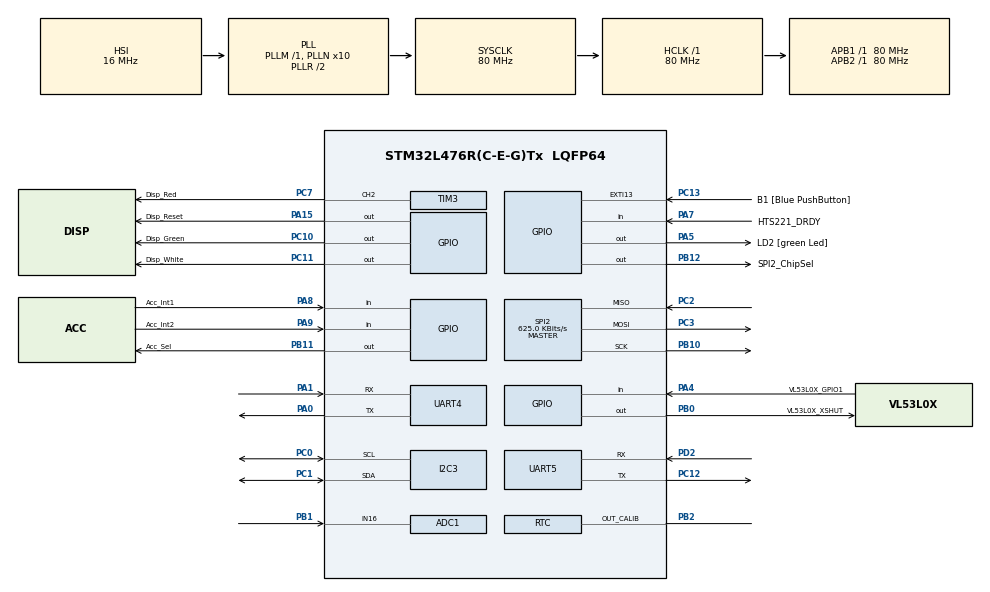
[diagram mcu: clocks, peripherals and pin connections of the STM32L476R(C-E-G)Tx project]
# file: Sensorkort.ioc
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ADC1.Channel-0\#ChannelRegularConversion=ADC_CHANNEL_16
ADC1.NbrOfConversionFlag=1
ADC1.OffsetNumber-0\#ChannelRegularConversion=ADC_OFFSET_NONE
ADC1.Rank-0\#ChannelRegularConversion=1
ADC1.SamplingTime-0\#ChannelRegularConversion=ADC_SAMPLETIME_2CYCLES_5
ADC1.master=1
Mcu.Family=STM32L4
Mcu.Name=STM32L476R(C-E-G)Tx
Mcu.Package=LQFP64
NVIC.PriorityGroup=NVIC_PRIORITYGROUP_4
PA0.Mode=Asynchronous
PA0.Signal=UART4_TX
PA1.Mode=Asynchronous
PA1.Signal=UART4_RX
PA13\ (JTMS-SWDIO).GPIO_Label=TMS
PA13\ (JTMS-SWDIO).Mode=Serial_Wire
PA13\ (JTMS-SWDIO).Signal=SYS_JTMS-SWDIO
PA14\ (JTCK-SWCLK).GPIO_Label=TCK
PA14\ (JTCK-SWCLK).Mode=Serial_Wire
PA14\ (JTCK-SWCLK).Signal=SYS_JTCK-SWCLK
PA15\ (JTDI).GPIO_Label=Disp_Reset
PA15\ (JTDI).PinState=GPIO_PIN_SET
PA15\ (JTDI).Signal=GPIO_Output
PA2.GPIO_Label=USART_TX
PA2.GPIO_Mode=GPIO_MODE_AF_PP
PA2.GPIO_PuPd=GPIO_NOPULL
PA2.GPIO_Speed=GPIO_SPEED_FREQ_VERY_HIGH
PA2.Signal=USART2_TX
PA3.GPIO_Label=USART_RX
PA3.GPIO_Mode=GPIO_MODE_AF_PP
PA3.GPIO_PuPd=GPIO_NOPULL
PA3.GPIO_Speed=GPIO_SPEED_FREQ_VERY_HIGH
PA3.Signal=USART2_RX
PA4.GPIO_Label=VL53L0X_GPIO1
PA4.Signal=GPIO_Input
PA5.GPIO_Label=LD2 [green Led]
PA5.GPIO_ModeDefaultOutputPP=GPIO_MODE_OUTPUT_PP
PA5.GPIO_PuPd=GPIO_NOPULL
PA5.GPIO_Speed=GPIO_SPEED_FREQ_LOW
PA5.Signal=GPIO_Output
PA7.GPIO_Label=HTS221_DRDY
PA7.Signal=GPIO_Input
PA8.GPIO_Label=Acc_Int1
PA8.Signal=GPIO_Input
PA9.GPIO_Label=Acc_Int2
PA9.Signal=GPIO_Input
PB0.GPIO_Label=VL53L0X_XSHUT
PB0.GPIO_ModeDefaultOutputPP=GPIO_MODE_OUTPUT_PP
PB0.PinState=GPIO_PIN_SET
PB0.Signal=GPIO_Output
PB1.Signal=ADCx_IN16
PB10.Mode=Full_Duplex_Master
PB10.Signal=SPI2_SCK
PB11.GPIO_Label=Acc_Sel
PB11.GPIO_ModeDefaultOutputPP=GPIO_MODE_OUTPUT_PP
PB11.Signal=GPIO_Output
PB12.GPIO_Label=SPI2_ChipSel
PB12.PinState=GPIO_PIN_SET
PB12.Signal=GPIO_Output
PB2.Mode=Calibration_1Hz
PB2.Signal=RTC_OUT_CALIB
PB3\ (JTDO-TRACESWO).GPIO_Label=SWO
PB3\ (JTDO-TRACESWO).Signal=SYS_JTDO-SWO
PC0.Mode=I2C
PC0.Signal=I2C3_SCL
PC1.Mode=I2C
PC1.Signal=I2C3_SDA
PC10.GPIO_Label=Disp_Green
PC10.Signal=GPIO_Output
PC11.GPIO_Label=Disp_White
PC11.Signal=GPIO_Output
PC12.Mode=Asynchronous
PC12.Signal=UART5_TX
PC13.GPIO_Label=B1 [Blue PushButton]
PC13.GPIO_ModeDefaultEXTI=GPIO_MODE_IT_FALLING
PC13.GPIO_PuPd=GPIO_NOPULL
PC13.Signal=GPXTI13
PC14-OSC32_IN\ (PC14).Mode=LSE-External-Oscillator
PC14-OSC32_IN\ (PC14).Signal=RCC_OSC32_IN
PC15-OSC32_OUT\ (PC15).Mode=LSE-External-Oscillator
PC15-OSC32_OUT\ (PC15).Signal=RCC_OSC32_OUT
PC2.Mode=Full_Duplex_Master
PC2.Signal=SPI2_MISO
PC3.Mode=Full_Duplex_Master
PC3.Signal=SPI2_MOSI
PC7.GPIO_Label=Disp_Red
PC7.Signal=S_TIM3_CH2
PD2.Mode=Asynchronous
PD2.Signal=UART5_RX
PH0-OSC_IN\ (PH0).Signal=RCC_OSC_IN
PH1-OSC_OUT\ (PH1).Signal=RCC_OSC_OUT
ProjectManager.HeapSize=0x200
ProjectManager.StackSize=0x400
ProjectManager.TargetToolchain=STM32CubeIDE
RCC.ADCFreq_Value=64000000
RCC.AHBFreq_Value=80000000
RCC.APB1Freq_Value=80000000
RCC.APB1TimFreq_Value=80000000
RCC.APB2Freq_Value=80000000
RCC.APB2TimFreq_Value=80000000
RCC.CortexFreq_Value=80000000
RCC.HCLKFreq_Value=80000000
RCC.HSE_VALUE=8000000
RCC.HSI_VALUE=16000000
RCC.MSI_VALUE=4000000
RCC.PLLN=10
RCC.PLLSourceVirtual=RCC_PLLSOURCE_HSI
RCC.PREFETCH_ENABLE=1
RCC.SYSCLKFreq_VALUE=80000000
RCC.SYSCLKSource=RCC_SYSCLKSOURCE_PLLCLK
RCC.USBFreq_Value=64000000
RCC.VCOOutputFreq_Value=160000000
RTC.Format=RTC_FORMAT_BIN
SH.ADCx_IN16.0=ADC1_IN16,IN16-Single-Ended
SH.S_TIM3_CH2.0=TIM3_CH2,PWM Generation2 CH2
SPI2.BaudRatePrescaler=SPI_BAUDRATEPRESCALER_128
SPI2.CLKPhase=SPI_PHASE_2EDGE
SPI2.CLKPolarity=SPI_POLARITY_HIGH
SPI2.CalculateBaudRate=625.0 KBits/s
SPI2.DataSize=SPI_DATASIZE_8BIT
SPI2.Direction=SPI_DIRECTION_2LINES
SPI2.FirstBit=SPI_FIRSTBIT_LSB
SPI2.Mode=SPI_MODE_MASTER
SPI2.VirtualType=VM_MASTER
TIM3.Channel-PWM\ Generation2\ CH2=TIM_CHANNEL_2
TIM3.Period=4000
VP_RTC_VS_RTC_Activate.Mode=RTC_Enabled
VP_RTC_VS_RTC_Calendar.Mode=RTC_Calendar
VP_TIM3_VS_ClockSourceINT.Mode=Internal
board=NUCLEO-L476RG

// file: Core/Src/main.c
/* USER CODE BEGIN Header */
/**
  ******************************************************************************
  * @file           : main.c
  * @brief          : Main program body
  ******************************************************************************
  * @attention
  *
  * <h2><center>&copy; Copyright (c) 2019 STMicroelectronics.
  * All rights reserved.</center></h2>
  *
  * This software component is licensed by ST under BSD 3-Clause license,
  * the "License"; You may not use this file except in compliance with the
  * License. You may obtain a copy of the License at:
  *                        opensource.org/licenses/BSD-3-Clause
  *
  ******************************************************************************
  */
/* USER CODE END Header */

#include "main.h"
#include "adc.h"
#include "i2c.h"
#include "rtc.h"
#include "spi.h"
#include "tim.h"
#include "usart.h"
#include "gpio.h"

/* USER CODE BEGIN Includes */
#include "../../Tests/Inc/display_test.h"
#include "../../Tests/Inc/rtc_test.h"
#include "../../Tests/Inc/usb_com_test.h"
#include "alt1_program.h"
/* USER CODE END Includes */

/* USER CODE BEGIN PD */
#define RUN_TEST_PROGRAM
/* USER CODE END PD */

void SystemClock_Config(void);

/* USER CODE BEGIN 0 */
#ifdef RUN_TEST_PROGRAM
extern void initialise_monitor_handles(void);
#endif
/* USER CODE END 0 */

int main(void)
{
  /* USER CODE BEGIN 1 */
#undef RUN_TEST_PROGRAM
  /* USER CODE END 1 */

  /* MCU Configuration--------------------------------------------------------*/

  /* Reset of all peripherals, Initializes the Flash interface and the Systick. */
  HAL_Init();

  /* Configure the system clock */
  SystemClock_Config();

  /* Initialize all configured peripherals */
  MX_GPIO_Init();
  MX_ADC1_Init();
  MX_I2C3_Init();
  MX_RTC_Init();
  MX_SPI2_Init();
  MX_UART4_Init();
  MX_UART5_Init();
  MX_TIM3_Init();
  /* USER CODE BEGIN 2 */
#ifdef RUN_TEST_PROGRAM
  display_test_program();
#else
  alt1_program();
#endif
  /* USER CODE END 2 */

  /* Infinite loop */
  while (1)
  {

  }
}

void SystemClock_Config(void)
{
  RCC_OscInitTypeDef RCC_OscInitStruct = {0};
  RCC_ClkInitTypeDef RCC_ClkInitStruct = {0};
  RCC_PeriphCLKInitTypeDef PeriphClkInit = {0};

  /** Initializes the CPU, AHB and APB busses clocks
  */
  RCC_OscInitStruct.OscillatorType = RCC_OSCILLATORTYPE_HSI|RCC_OSCILLATORTYPE_LSI;
  RCC_OscInitStruct.HSIState = RCC_HSI_ON;
  RCC_OscInitStruct.HSICalibrationValue = RCC_HSICALIBRATION_DEFAULT;
  RCC_OscInitStruct.LSIState = RCC_LSI_ON;
  RCC_OscInitStruct.PLL.PLLState = RCC_PLL_ON;
  RCC_OscInitStruct.PLL.PLLSource = RCC_PLLSOURCE_HSI;
  RCC_OscInitStruct.PLL.PLLM = 1;
  RCC_OscInitStruct.PLL.PLLN = 10;
  RCC_OscInitStruct.PLL.PLLP = RCC_PLLP_DIV7;
  RCC_OscInitStruct.PLL.PLLQ = RCC_PLLQ_DIV2;
  RCC_OscInitStruct.PLL.PLLR = RCC_PLLR_DIV2;
  if (HAL_RCC_OscConfig(&RCC_OscInitStruct) != HAL_OK)
  {
    Error_Handler();
  }
  /** Initializes the CPU, AHB and APB busses clocks
  */
  RCC_ClkInitStruct.ClockType = RCC_CLOCKTYPE_HCLK|RCC_CLOCKTYPE_SYSCLK
                              |RCC_CLOCKTYPE_PCLK1|RCC_CLOCKTYPE_PCLK2;
  RCC_ClkInitStruct.SYSCLKSource = RCC_SYSCLKSOURCE_PLLCLK;
  RCC_ClkInitStruct.AHBCLKDivider = RCC_SYSCLK_DIV1;
  RCC_ClkInitStruct.APB1CLKDivider = RCC_HCLK_DIV1;
  RCC_ClkInitStruct.APB2CLKDivider = RCC_HCLK_DIV1;

  if (HAL_RCC_ClockConfig(&RCC_ClkInitStruct, FLASH_LATENCY_4) != HAL_OK)
  {
    Error_Handler();
  }
  PeriphClkInit.PeriphClockSelection = RCC_PERIPHCLK_RTC|RCC_PERIPHCLK_UART4
                              |RCC_PERIPHCLK_UART5|RCC_PERIPHCLK_I2C3
                              |RCC_PERIPHCLK_ADC;
  PeriphClkInit.Uart4ClockSelection = RCC_UART4CLKSOURCE_PCLK1;
  PeriphClkInit.Uart5ClockSelection = RCC_UART5CLKSOURCE_PCLK1;
  PeriphClkInit.I2c3ClockSelection = RCC_I2C3CLKSOURCE_PCLK1;
  PeriphClkInit.AdcClockSelection = RCC_ADCCLKSOURCE_PLLSAI1;
  PeriphClkInit.RTCClockSelection = RCC_RTCCLKSOURCE_LSI;
  PeriphClkInit.PLLSAI1.PLLSAI1Source = RCC_PLLSOURCE_HSI;
  PeriphClkInit.PLLSAI1.PLLSAI1M = 1;
  PeriphClkInit.PLLSAI1.PLLSAI1N = 8;
  PeriphClkInit.PLLSAI1.PLLSAI1P = RCC_PLLP_DIV7;
  PeriphClkInit.PLLSAI1.PLLSAI1Q = RCC_PLLQ_DIV2;
  PeriphClkInit.PLLSAI1.PLLSAI1R = RCC_PLLR_DIV2;
  PeriphClkInit.PLLSAI1.PLLSAI1ClockOut = RCC_PLLSAI1_ADC1CLK;
  if (HAL_RCCEx_PeriphCLKConfig(&PeriphClkInit) != HAL_OK)
  {
    Error_Handler();
  }
  /** Configure the main internal regulator output voltage
  */
  if (HAL_PWREx_ControlVoltageScaling(PWR_REGULATOR_VOLTAGE_SCALE1) != HAL_OK)
  {
    Error_Handler();
  }
}

void Error_Handler(void)
{
}

/************************ (C) COPYRIGHT STMicroelectronics *****END OF FILE****/
